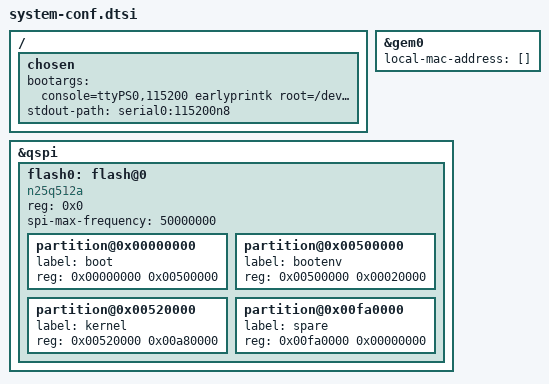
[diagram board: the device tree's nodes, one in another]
/*
 * CAUTION: This file is automatically generated by PetaLinux SDK.
 * DO NOT modify this file
 */


/ {
	chosen {
		bootargs = "console=ttyPS0,115200 earlyprintk root=/dev/mmcblk0p2 rw rootwait";
		stdout-path = "serial0:115200n8";
	};
};

&gem0 {
	local-mac-address = [];
};

&qspi {
	#address-cells = <1>;
	#size-cells = <0>;
	flash0: flash@0 {
		compatible = "n25q512a","micron,m25p80";
		reg = <0x0>;
		#address-cells = <1>;
		#size-cells = <1>;
		spi-max-frequency = <50000000>;
		partition@0x00000000 {
			label = "boot";
			reg = <0x00000000 0x00500000>;
		};
		partition@0x00500000 {
			label = "bootenv";
			reg = <0x00500000 0x00020000>;
		};
		partition@0x00520000 {
			label = "kernel";
			reg = <0x00520000 0x00a80000>;
		};
		partition@0x00fa0000 {
			label = "spare";
			reg = <0x00fa0000 0x00000000>;
		};
	};
};

